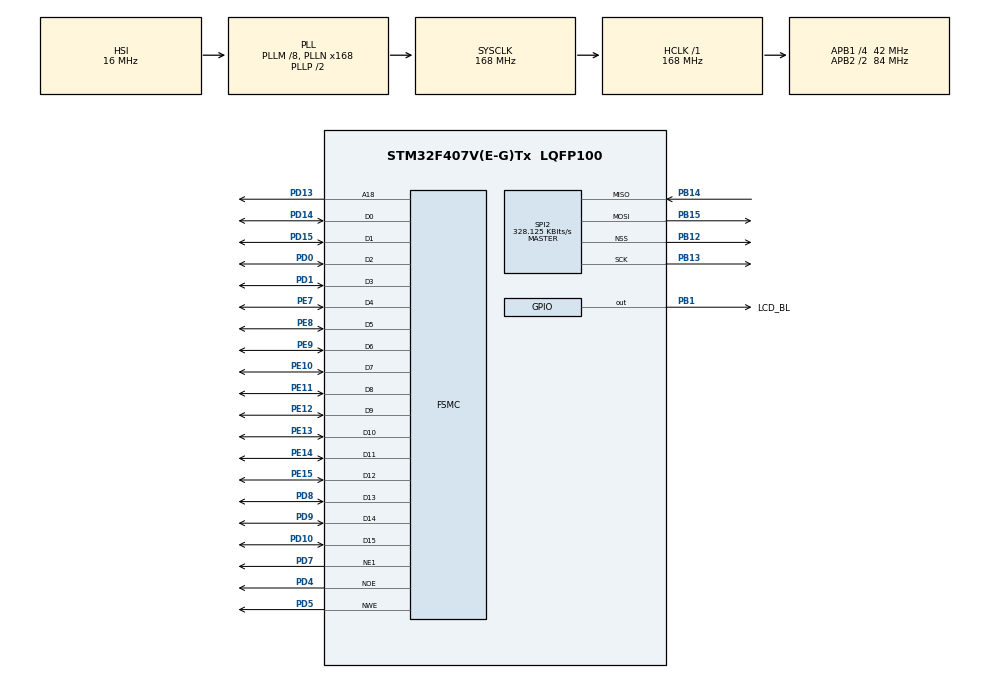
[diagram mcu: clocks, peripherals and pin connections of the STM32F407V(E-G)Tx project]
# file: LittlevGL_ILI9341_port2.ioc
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FSMC.AddressSetupTime1=1
FSMC.BusTurnAroundDuration1=0
FSMC.DataSetupTime1=5
Mcu.Family=STM32F4
Mcu.Name=STM32F407V(E-G)Tx
Mcu.Package=LQFP100
NVIC.PriorityGroup=NVIC_PRIORITYGROUP_4
PA13.Mode=Serial_Wire
PA13.Signal=SYS_JTMS-SWDIO
PA14.Mode=Serial_Wire
PA14.Signal=SYS_JTCK-SWCLK
PB1.GPIO_Label=LCD_BL
PB1.PinState=GPIO_PIN_SET
PB1.Signal=GPIO_Output
PB12.Mode=NSS_Signal_Hard_Output
PB12.Signal=SPI2_NSS
PB13.Mode=Full_Duplex_Master
PB13.Signal=SPI2_SCK
PB14.Mode=Full_Duplex_Master
PB14.Signal=SPI2_MISO
PB15.Mode=Full_Duplex_Master
PB15.Signal=SPI2_MOSI
PC14-OSC32_IN.Mode=LSE-External-Oscillator
PC14-OSC32_IN.Signal=RCC_OSC32_IN
PC15-OSC32_OUT.Mode=LSE-External-Oscillator
PC15-OSC32_OUT.Signal=RCC_OSC32_OUT
PD0.Mode=16b-d1
PD0.Signal=FSMC_D2
PD1.Mode=16b-d1
PD1.Signal=FSMC_D3
PD10.Mode=16b-d1
PD10.Signal=FSMC_D15
PD13.Mode=A18_1
PD13.Signal=FSMC_A18
PD14.Mode=16b-d1
PD14.Signal=FSMC_D0
PD15.Mode=16b-d1
PD15.Signal=FSMC_D1
PD4.Mode=Lcd1
PD4.Signal=FSMC_NOE
PD5.Mode=Lcd1
PD5.Signal=FSMC_NWE
PD7.Mode=NorPsramChipSelect1_1
PD7.Signal=FSMC_NE1
PD8.Mode=16b-d1
PD8.Signal=FSMC_D13
PD9.Mode=16b-d1
PD9.Signal=FSMC_D14
PE10.Mode=16b-d1
PE10.Signal=FSMC_D7
PE11.Mode=16b-d1
PE11.Signal=FSMC_D8
PE12.Mode=16b-d1
PE12.Signal=FSMC_D9
PE13.Mode=16b-d1
PE13.Signal=FSMC_D10
PE14.Mode=16b-d1
PE14.Signal=FSMC_D11
PE15.Mode=16b-d1
PE15.Signal=FSMC_D12
PE7.Mode=16b-d1
PE7.Signal=FSMC_D4
PE8.Mode=16b-d1
PE8.Signal=FSMC_D5
PE9.Mode=16b-d1
PE9.Signal=FSMC_D6
PH0-OSC_IN.Mode=HSE-External-Oscillator
PH0-OSC_IN.Signal=RCC_OSC_IN
PH1-OSC_OUT.Mode=HSE-External-Oscillator
PH1-OSC_OUT.Signal=RCC_OSC_OUT
ProjectManager.HeapSize=0x200
ProjectManager.StackSize=0x400
ProjectManager.TargetToolchain=STM32CubeIDE
RCC.48MHZClocksFreq_Value=84000000
RCC.AHBFreq_Value=168000000
RCC.APB1CLKDivider=RCC_HCLK_DIV4
RCC.APB1Freq_Value=42000000
RCC.APB1TimFreq_Value=84000000
RCC.APB2CLKDivider=RCC_HCLK_DIV2
RCC.APB2Freq_Value=84000000
RCC.APB2TimFreq_Value=168000000
RCC.CortexFreq_Value=168000000
RCC.HCLKFreq_Value=168000000
RCC.HSE_VALUE=8000000
RCC.HSI_VALUE=16000000
RCC.PLLM=8
RCC.PLLN=168
RCC.SYSCLKFreq_VALUE=168000000
RCC.SYSCLKSource=RCC_SYSCLKSOURCE_PLLCLK
RCC.VCOOutputFreq_Value=336000000
SPI2.BaudRatePrescaler=SPI_BAUDRATEPRESCALER_128
SPI2.CalculateBaudRate=328.125 KBits/s
SPI2.Direction=SPI_DIRECTION_2LINES
SPI2.FirstBit=SPI_FIRSTBIT_MSB
SPI2.Mode=SPI_MODE_MASTER
SPI2.VirtualNSS=VM_NSSHARD
SPI2.VirtualType=VM_MASTER
board=custom

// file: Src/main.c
/* USER CODE BEGIN Header */
/**
  ******************************************************************************
  * @file           : main.c
  * @brief          : Main program body
  ******************************************************************************
  * @attention
  *
  * <h2><center>&copy; Copyright (c) 2020 STMicroelectronics.
  * All rights reserved.</center></h2>
  *
  * This software component is licensed by ST under BSD 3-Clause license,
  * the "License"; You may not use this file except in compliance with the
  * License. You may obtain a copy of the License at:
  *                        opensource.org/licenses/BSD-3-Clause
  *
  ******************************************************************************
  */
/* USER CODE END Header */

#include "main.h"

/* USER CODE BEGIN Includes */
#include "lvgl/porting/lv_port_disp_template.h"
#include "lvgl/porting/lv_port_indev_template.h"
#include "lvgl/lvgl.h"
#include <stdlib.h>
#include <stdio.h>
#include <stdint.h>
#include "demo/demo.h"

#include "hw/XPT2046.h"

/* USER CODE END Includes */

SPI_HandleTypeDef hspi2;

SRAM_HandleTypeDef hsram1;

void SystemClock_Config(void);
static void MX_GPIO_Init(void);
static void MX_FSMC_Init(void);
static void MX_SPI2_Init(void);

int main(void)
{

  /* MCU Configuration--------------------------------------------------------*/

  /* Reset of all peripherals, Initializes the Flash interface and the Systick. */
  HAL_Init();

  /* Configure the system clock */
  SystemClock_Config();

  /* Initialize all configured peripherals */
  MX_GPIO_Init();
  MX_FSMC_Init();
  MX_SPI2_Init();
  /* USER CODE BEGIN 2 */

  lv_init();
  lv_port_disp_init();
  lv_port_indev_init();

//  lv_obj_t * scr = lv_disp_get_scr_act(NULL);     /*Get the current screen*/
//  lv_obj_t * label1 =  lv_label_create(scr, NULL);
//  lv_obj_t * label2 =  lv_label_create(scr, NULL);
//  lv_obj_t * label3 =  lv_label_create(scr, NULL);
//  lv_obj_t * label4 =  lv_label_create(scr, NULL);
//  lv_obj_t * label5 =  lv_label_create(scr, NULL);
//  lv_obj_align(label1, NULL, LV_ALIGN_IN_TOP_LEFT, 10, 0);
//  lv_obj_align(label2, NULL, LV_ALIGN_IN_TOP_LEFT, 10, 20);
//  lv_obj_align(label3, NULL, LV_ALIGN_IN_TOP_LEFT, 10, 40);
//  lv_obj_align(label4, NULL, LV_ALIGN_IN_TOP_LEFT, 10, 60);
//  lv_obj_align(label5, NULL, LV_ALIGN_IN_TOP_LEFT, 10, 80);

  /* USER CODE END 2 */
  demo_create();

  /* Infinite loop */
  while (1)
  {

    /* USER CODE BEGIN 3 */

//	  static uint32_t cnt = 0;
//	  static char str[50];
//	  uint16_t touchX = 0, touchY = 0, touchZ = 0, press = 0;
//	  press = Get_Touch_XY(&touchX, &touchY, 10, 0);
//	  Get_Touch_Z(&touchZ);
//	  sprintf(str, "Counter = %lu", cnt++);
//	  lv_label_set_text(label1, str);
//	  sprintf(str, "X = %i", touchX);
//	  lv_label_set_text(label2, str);
//	  sprintf(str, "Y = %i", touchY);
//	  lv_label_set_text(label3, str);
//	  sprintf(str, "Z = %i", touchZ);
//	  lv_label_set_text(label4, str);
//	  sprintf(str, "Pressed = %i", press);
//	  lv_label_set_text(label5, str);

	  HAL_Delay(10);
	  lv_task_handler();

  }
  /* USER CODE END 3 */
}

void SystemClock_Config(void)
{
  RCC_OscInitTypeDef RCC_OscInitStruct = {0};
  RCC_ClkInitTypeDef RCC_ClkInitStruct = {0};

  /** Configure the main internal regulator output voltage
  */
  __HAL_RCC_PWR_CLK_ENABLE();
  __HAL_PWR_VOLTAGESCALING_CONFIG(PWR_REGULATOR_VOLTAGE_SCALE1);
  /** Initializes the CPU, AHB and APB busses clocks
  */
  RCC_OscInitStruct.OscillatorType = RCC_OSCILLATORTYPE_HSI;
  RCC_OscInitStruct.HSIState = RCC_HSI_ON;
  RCC_OscInitStruct.HSICalibrationValue = RCC_HSICALIBRATION_DEFAULT;
  RCC_OscInitStruct.PLL.PLLState = RCC_PLL_ON;
  RCC_OscInitStruct.PLL.PLLSource = RCC_PLLSOURCE_HSI;
  RCC_OscInitStruct.PLL.PLLM = 8;
  RCC_OscInitStruct.PLL.PLLN = 168;
  RCC_OscInitStruct.PLL.PLLP = RCC_PLLP_DIV2;
  RCC_OscInitStruct.PLL.PLLQ = 4;
  if (HAL_RCC_OscConfig(&RCC_OscInitStruct) != HAL_OK)
  {
    Error_Handler();
  }
  /** Initializes the CPU, AHB and APB busses clocks
  */
  RCC_ClkInitStruct.ClockType = RCC_CLOCKTYPE_HCLK|RCC_CLOCKTYPE_SYSCLK
                              |RCC_CLOCKTYPE_PCLK1|RCC_CLOCKTYPE_PCLK2;
  RCC_ClkInitStruct.SYSCLKSource = RCC_SYSCLKSOURCE_PLLCLK;
  RCC_ClkInitStruct.AHBCLKDivider = RCC_SYSCLK_DIV1;
  RCC_ClkInitStruct.APB1CLKDivider = RCC_HCLK_DIV4;
  RCC_ClkInitStruct.APB2CLKDivider = RCC_HCLK_DIV2;

  if (HAL_RCC_ClockConfig(&RCC_ClkInitStruct, FLASH_LATENCY_5) != HAL_OK)
  {
    Error_Handler();
  }
}

static void MX_SPI2_Init(void)
{

  /* SPI2 parameter configuration*/
  hspi2.Instance = SPI2;
  hspi2.Init.Mode = SPI_MODE_MASTER;
  hspi2.Init.Direction = SPI_DIRECTION_2LINES;
  hspi2.Init.DataSize = SPI_DATASIZE_8BIT;
  hspi2.Init.CLKPolarity = SPI_POLARITY_LOW;
  hspi2.Init.CLKPhase = SPI_PHASE_1EDGE;
  hspi2.Init.NSS = SPI_NSS_HARD_OUTPUT;
  hspi2.Init.BaudRatePrescaler = SPI_BAUDRATEPRESCALER_128;
  hspi2.Init.FirstBit = SPI_FIRSTBIT_MSB;
  hspi2.Init.TIMode = SPI_TIMODE_DISABLE;
  hspi2.Init.CRCCalculation = SPI_CRCCALCULATION_DISABLE;
  hspi2.Init.CRCPolynomial = 10;
  if (HAL_SPI_Init(&hspi2) != HAL_OK)
  {
    Error_Handler();
  }

}

static void MX_GPIO_Init(void)
{
  GPIO_InitTypeDef GPIO_InitStruct = {0};

  /* GPIO Ports Clock Enable */
  __HAL_RCC_GPIOC_CLK_ENABLE();
  __HAL_RCC_GPIOH_CLK_ENABLE();
  __HAL_RCC_GPIOB_CLK_ENABLE();
  __HAL_RCC_GPIOE_CLK_ENABLE();
  __HAL_RCC_GPIOD_CLK_ENABLE();
  __HAL_RCC_GPIOA_CLK_ENABLE();

  /*Configure GPIO pin Output Level */
  HAL_GPIO_WritePin(LCD_BL_GPIO_Port, LCD_BL_Pin, GPIO_PIN_SET);

  /*Configure GPIO pin : LCD_BL_Pin */
  GPIO_InitStruct.Pin = LCD_BL_Pin;
  GPIO_InitStruct.Mode = GPIO_MODE_OUTPUT_PP;
  GPIO_InitStruct.Pull = GPIO_NOPULL;
  GPIO_InitStruct.Speed = GPIO_SPEED_FREQ_LOW;
  HAL_GPIO_Init(LCD_BL_GPIO_Port, &GPIO_InitStruct);

}

/* FSMC initialization function */
static void MX_FSMC_Init(void)
{

  FSMC_NORSRAM_TimingTypeDef Timing = {0};

  /** Perform the SRAM1 memory initialization sequence
  */
  hsram1.Instance = FSMC_NORSRAM_DEVICE;
  hsram1.Extended = FSMC_NORSRAM_EXTENDED_DEVICE;
  /* hsram1.Init */
  hsram1.Init.NSBank = FSMC_NORSRAM_BANK1;
  hsram1.Init.DataAddressMux = FSMC_DATA_ADDRESS_MUX_DISABLE;
  hsram1.Init.MemoryType = FSMC_MEMORY_TYPE_SRAM;
  hsram1.Init.MemoryDataWidth = FSMC_NORSRAM_MEM_BUS_WIDTH_16;
  hsram1.Init.BurstAccessMode = FSMC_BURST_ACCESS_MODE_DISABLE;
  hsram1.Init.WaitSignalPolarity = FSMC_WAIT_SIGNAL_POLARITY_LOW;
  hsram1.Init.WrapMode = FSMC_WRAP_MODE_DISABLE;
  hsram1.Init.WaitSignalActive = FSMC_WAIT_TIMING_BEFORE_WS;
  hsram1.Init.WriteOperation = FSMC_WRITE_OPERATION_ENABLE;
  hsram1.Init.WaitSignal = FSMC_WAIT_SIGNAL_DISABLE;
  hsram1.Init.ExtendedMode = FSMC_EXTENDED_MODE_DISABLE;
  hsram1.Init.AsynchronousWait = FSMC_ASYNCHRONOUS_WAIT_DISABLE;
  hsram1.Init.WriteBurst = FSMC_WRITE_BURST_DISABLE;
  hsram1.Init.PageSize = FSMC_PAGE_SIZE_NONE;
  /* Timing */
  Timing.AddressSetupTime = 1;
  Timing.AddressHoldTime = 15;
  Timing.DataSetupTime = 5;
  Timing.BusTurnAroundDuration = 0;
  Timing.CLKDivision = 16;
  Timing.DataLatency = 17;
  Timing.AccessMode = FSMC_ACCESS_MODE_A;
  /* ExtTiming */

  if (HAL_SRAM_Init(&hsram1, &Timing, NULL) != HAL_OK)
  {
    Error_Handler( );
  }

}

void Error_Handler(void)
{
}

/************************ (C) COPYRIGHT STMicroelectronics *****END OF FILE****/
